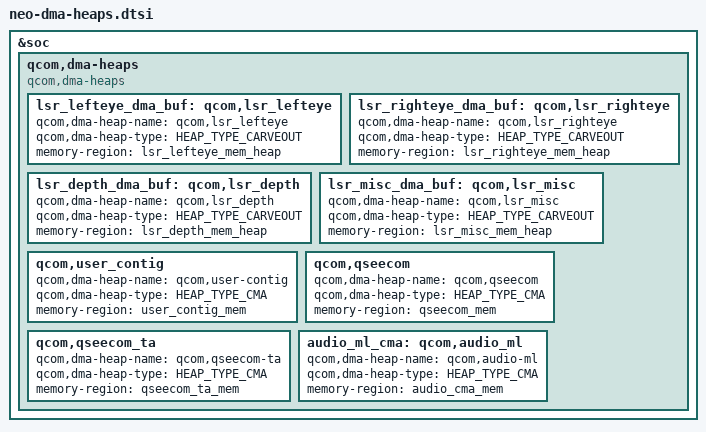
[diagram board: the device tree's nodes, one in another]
#include <dt-bindings/arm/msm/qcom_dma_heap_dt_constants.h>

&soc {
	qcom,dma-heaps {
		compatible = "qcom,dma-heaps";

		lsr_lefteye_dma_buf: qcom,lsr_lefteye {
			qcom,dma-heap-name = "qcom,lsr_lefteye";
			qcom,dma-heap-type = <HEAP_TYPE_CARVEOUT>;
			memory-region = <&lsr_lefteye_mem_heap>;
		};

		lsr_righteye_dma_buf: qcom,lsr_righteye {
			qcom,dma-heap-name = "qcom,lsr_righteye";
			qcom,dma-heap-type = <HEAP_TYPE_CARVEOUT>;
			memory-region = <&lsr_righteye_mem_heap>;
		};

		lsr_depth_dma_buf: qcom,lsr_depth {
			qcom,dma-heap-name = "qcom,lsr_depth";
			qcom,dma-heap-type = <HEAP_TYPE_CARVEOUT>;
			memory-region = <&lsr_depth_mem_heap>;
		};

		lsr_misc_dma_buf: qcom,lsr_misc {
			qcom,dma-heap-name = "qcom,lsr_misc";
			qcom,dma-heap-type = <HEAP_TYPE_CARVEOUT>;
			memory-region = <&lsr_misc_mem_heap>;
		};

		qcom,user_contig {
			qcom,dma-heap-name = "qcom,user-contig";
			qcom,dma-heap-type = <HEAP_TYPE_CMA>;
			memory-region = <&user_contig_mem>;
		};

		qcom,qseecom {
			qcom,dma-heap-name = "qcom,qseecom";
			qcom,dma-heap-type = <HEAP_TYPE_CMA>;
			memory-region = <&qseecom_mem>;
		};

		qcom,qseecom_ta {
			qcom,dma-heap-name = "qcom,qseecom-ta";
			qcom,dma-heap-type = <HEAP_TYPE_CMA>;
			memory-region = <&qseecom_ta_mem>;
		};
		audio_ml_cma: qcom,audio_ml {
			qcom,dma-heap-name = "qcom,audio-ml";
			qcom,dma-heap-type = <HEAP_TYPE_CMA>;
			memory-region = <&audio_cma_mem>;
		};
	};
};
